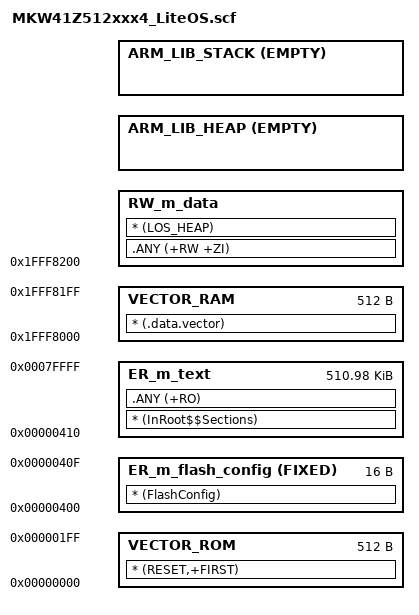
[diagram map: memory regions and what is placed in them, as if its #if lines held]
#! armcc -E
/*
** ###################################################################
**     Processors:          MKW41Z512CAT4
**                          MKW41Z512VHT4
**
**     Compiler:            Keil ARM C/C++ Compiler
**     Reference manual:    MKW41Z512RM Rev. 0.1, 04/2016
**     Version:             rev. 1.0, 2015-09-23
**     Build:               b170214
**
**     Abstract:
**         Linker file for the Keil ARM C/C++ Compiler
**
**     Copyright 2016 Freescale Semiconductor, Inc.
**     Copyright 2016-2017 NXP
**     Redistribution and use in source and binary forms, with or without modification,
**     are permitted provided that the following conditions are met:
**
**     o Redistributions of source code must retain the above copyright notice, this list
**       of conditions and the following disclaimer.
**
**     o Redistributions in binary form must reproduce the above copyright notice, this
**       list of conditions and the following disclaimer in the documentation and/or
**       other materials provided with the distribution.
**
**     o Neither the name of the copyright holder nor the names of its
**       contributors may be used to endorse or promote products derived from this
**       software without specific prior written permission.
**
**     THIS SOFTWARE IS PROVIDED BY THE COPYRIGHT HOLDERS AND CONTRIBUTORS "AS IS" AND
**     ANY EXPRESS OR IMPLIED WARRANTIES, INCLUDING, BUT NOT LIMITED TO, THE IMPLIED
**     WARRANTIES OF MERCHANTABILITY AND FITNESS FOR A PARTICULAR PURPOSE ARE
**     DISCLAIMED. IN NO EVENT SHALL THE COPYRIGHT HOLDER OR CONTRIBUTORS BE LIABLE FOR
**     ANY DIRECT, INDIRECT, INCIDENTAL, SPECIAL, EXEMPLARY, OR CONSEQUENTIAL DAMAGES
**     (INCLUDING, BUT NOT LIMITED TO, PROCUREMENT OF SUBSTITUTE GOODS OR SERVICES;
**     LOSS OF USE, DATA, OR PROFITS; OR BUSINESS INTERRUPTION) HOWEVER CAUSED AND ON
**     ANY THEORY OF LIABILITY, WHETHER IN CONTRACT, STRICT LIABILITY, OR TORT
**     (INCLUDING NEGLIGENCE OR OTHERWISE) ARISING IN ANY WAY OUT OF THE USE OF THIS
**     SOFTWARE, EVEN IF ADVISED OF THE POSSIBILITY OF SUCH DAMAGE.
**
**     http:                 www.nxp.com
**     mail:                 support@nxp.com
**
** ###################################################################
*/

/**
 * LiteOS启动后会将中断向量表重映射到RAM的起始位置，故在此处增加对LiteOS中断向量表重映射的支持，原有的中断向量表
 * 仍然位于FLASH的起始位置，这样在FLASH和RAM中各有一份中断向量表，FLASH中的向量表不能更改，RAM中的向量表可以动态
 * 修改
 * 开启宏__ram_vector_table__，并加入LiteOS相关参数
 */

#define __ram_vector_table__

#if (defined(__ram_vector_table__))
  #define __ram_vector_table_size__    0x00000200
#else
  #define __ram_vector_table_size__    0x00000000
#endif

#define m_interrupts_start             0x00000000
#define m_interrupts_size              0x00000200

#define m_flash_config_start           0x00000400
#define m_flash_config_size            0x00000010

#define m_text_start                   0x00000410
#define m_text_size                    0x0007FBF0

#define m_interrupts_ram_start         0x1FFF8000
#define m_interrupts_ram_size          __ram_vector_table_size__

#define m_data_start                   (m_interrupts_ram_start + m_interrupts_ram_size)
#define m_data_size                    (0x00020000 - m_interrupts_ram_size)

/* Sizes */
#if (defined(__stack_size__))
  #define Stack_Size                   __stack_size__
#else
  #define Stack_Size                   0x0400
#endif

#if (defined(__heap_size__))
  #define Heap_Size                    __heap_size__
#else
  #define Heap_Size                    0x0400
#endif

LR_m_text m_interrupts_start m_text_start+m_text_size-m_interrupts_start { ; load region size_region
  VECTOR_ROM m_interrupts_start m_interrupts_size { ; load address = execution address
    * (RESET,+FIRST)
  }
  ER_m_flash_config m_flash_config_start FIXED m_flash_config_size { ; load address = execution address
    * (FlashConfig)
  }
  ER_m_text m_text_start m_text_size { ; load address = execution address
    * (InRoot$$Sections)
    .ANY (+RO)
  }

#if (defined(__ram_vector_table__))
  VECTOR_RAM m_interrupts_ram_start m_interrupts_ram_size {
    * (.data.vector)
  }
#else
  VECTOR_RAM m_interrupts_start EMPTY 0 {
  }
#endif

  RW_m_data m_data_start m_data_size-Stack_Size-Heap_Size { ; RW data
    .ANY (+RW +ZI)
    * (LOS_HEAP)
  }
  ARM_LIB_HEAP +0 EMPTY Heap_Size {    ; Heap region growing up
  }
  ARM_LIB_STACK m_data_start+m_data_size EMPTY -Stack_Size { ; Stack region growing down
  }
}

